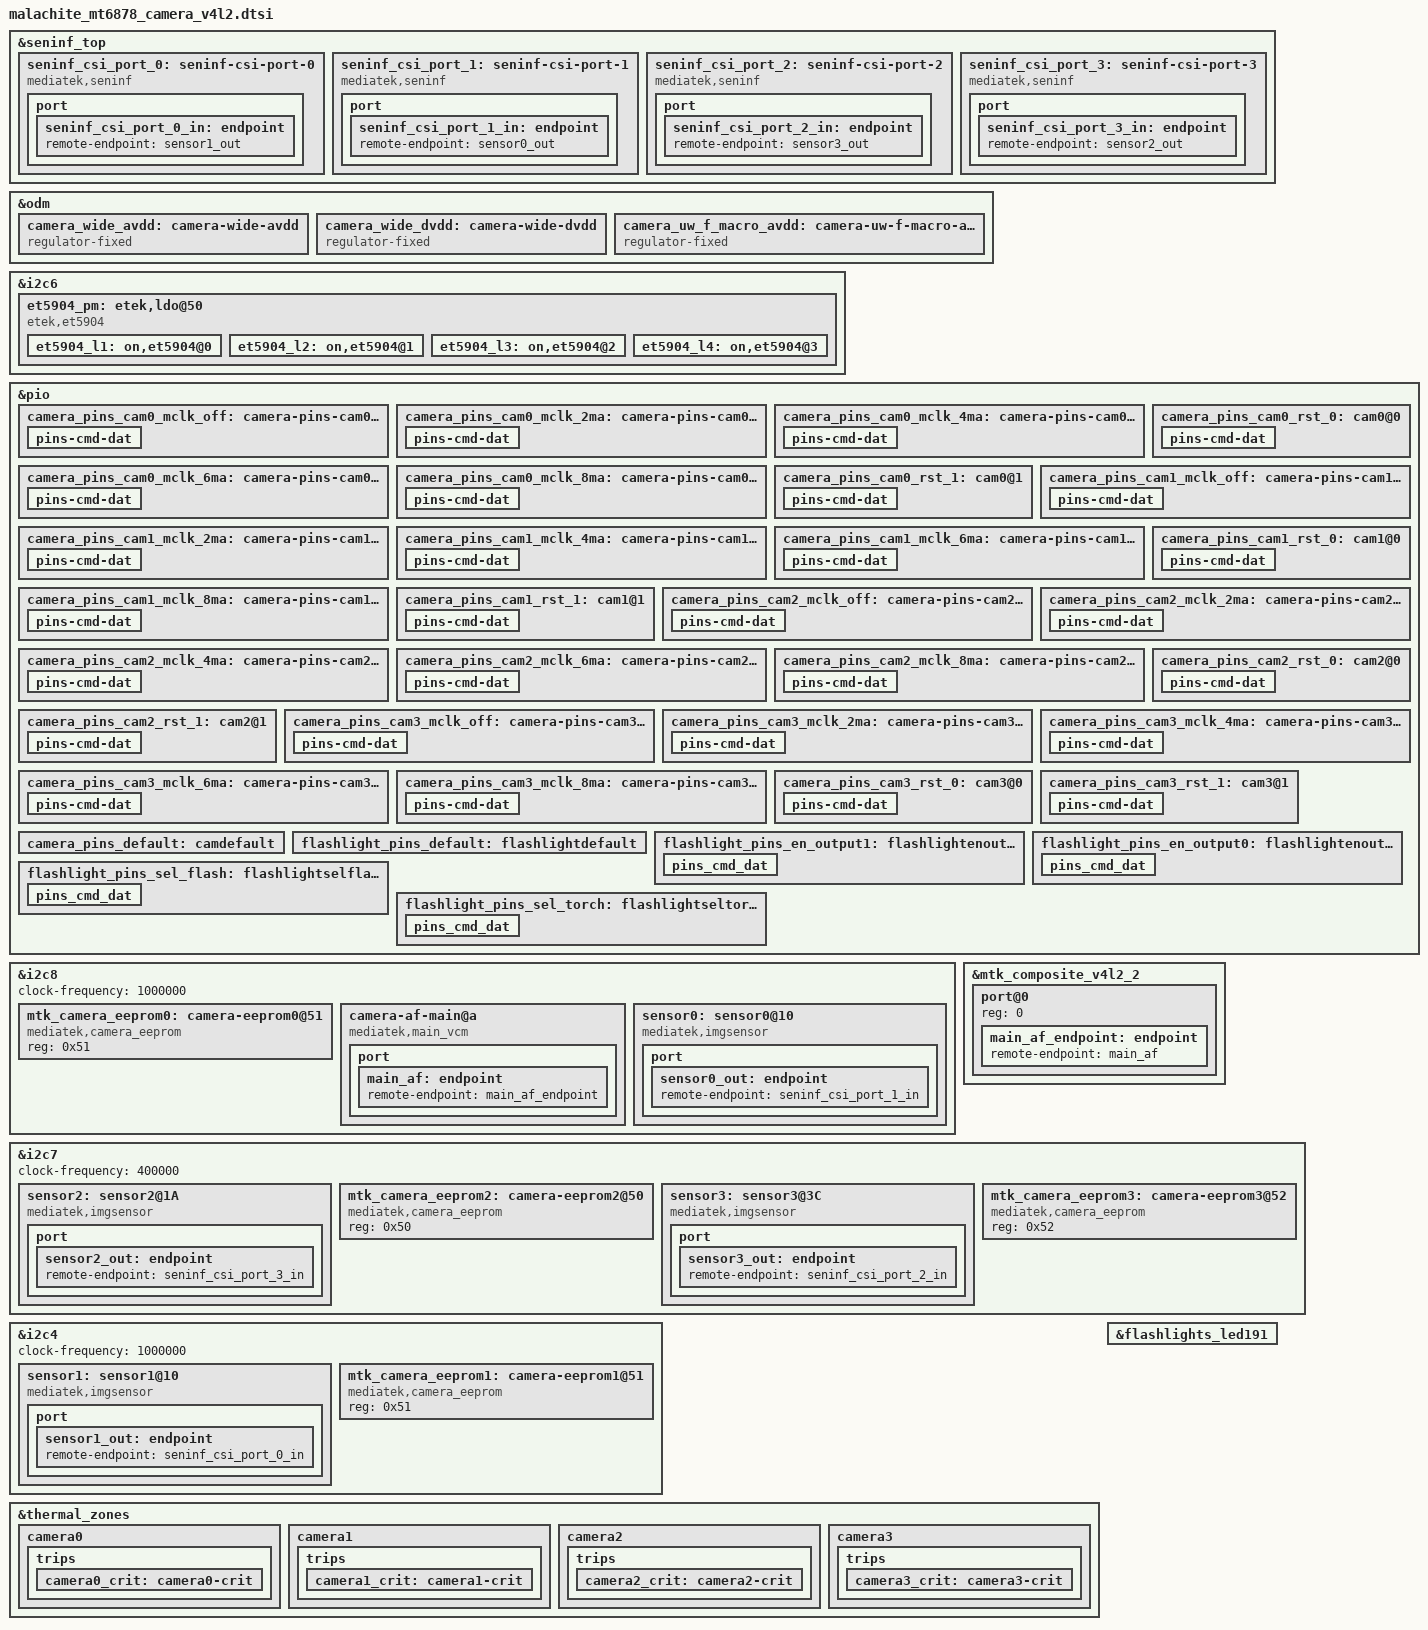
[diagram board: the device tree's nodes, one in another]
// SPDX-License-Identifier: GPL-2.0
/* Copyright (c) 2020 MediaTek Inc. */
#include <dt-bindings/clock/mt6878-clk.h>

&seninf_top {
		seninf_csi_port_0: seninf-csi-port-0 {
			compatible = "mediatek,seninf";
			csi-port = "0";
			nvmem-cells = <&csi_efuse0>;
			nvmem-cell-names = "rg_csi";
			port {
				seninf_csi_port_0_in: endpoint {
					remote-endpoint = <&sensor1_out>;
				};
			};
		};

		seninf_csi_port_1: seninf-csi-port-1 {

			compatible = "mediatek,seninf";
			csi-port = "1";
			nvmem-cells = <&csi_efuse1>;
			nvmem-cell-names = "rg_csi";
			port {
				seninf_csi_port_1_in: endpoint {
					remote-endpoint = <&sensor0_out>;
				};
			};
		};

		seninf_csi_port_2: seninf-csi-port-2 {
			compatible = "mediatek,seninf";
			csi-port = "2B";
			nvmem-cells = <&csi_efuse2>;
			nvmem-cell-names = "rg_csi";
			port {
				seninf_csi_port_2_in: endpoint {
					remote-endpoint = <&sensor3_out>;
				};
			};
		};
		seninf_csi_port_3: seninf-csi-port-3 {
			compatible = "mediatek,seninf";
			csi-port = "3";
			nvmem-cells = <&csi_efuse3>;
			nvmem-cell-names = "rg_csi";
			port {
				seninf_csi_port_3_in: endpoint {
					remote-endpoint = <&sensor2_out>;
				};
			};
		};
};

/* CAMERA GPIO fixed to regulator */
&odm {
	camera_wide_avdd: camera-wide-avdd {
		compatible = "regulator-fixed";
		regulator-name = "camera-wide-avdd";
		regulator-min-microvolt = <2800000>;
		regulator-max-microvolt = <2800000>;
		enable-active-high;
		gpio = <&pio 23 0x0>;
	};
	camera_wide_dvdd: camera-wide-dvdd {
		compatible = "regulator-fixed";
		regulator-name = "camera-wide-dvdd";
		regulator-min-microvolt = <1200000>;
		regulator-max-microvolt = <1200000>;
		enable-active-high;
		gpio = <&pio 191 0x0>;
	};
	camera_uw_f_macro_avdd: camera-uw-f-macro-avdd {
		compatible = "regulator-fixed";
		regulator-name = "camera-uw-f-macro-avdd";
		regulator-min-microvolt = <2800000>;
		regulator-max-microvolt = <2800000>;
		enable-active-high;
		gpio = <&pio 185 0x0>;
	};
};


&i2c6 {
	#address-cells = <1>;
	#size-cells = <0>;

	et5904_pm:etek,ldo@50 {
		compatible = "etek,et5904";
		reg = <0x50>;/*slave address*/
		index = <0>;
		BoardId_gpio1 = <&pio 105 0x0>;
		BoardId_gpio2 = <&pio 106 0x0>;
		BoardId_gpio3 = <&pio 113 0x0>;

		et5904_l1:on,et5904@0{
			offset = /bits/ 16 <0x0000>;
			regulator-name ="et5904-l1";
			regulator-min-microvolt = <528000>;
			regulator-max-microvolt = <1504000>;
			min-dropout-voltage = <225000>;
			init-voltage = <1200000>;
			iout_ua = <650000>;
		};

		et5904_l2:on,et5904@1{
			offset = /bits/ 16 <0x0001>;
			regulator-name ="et5904-l2";
			regulator-min-microvolt = <528000>;
			regulator-max-microvolt = <1504000>;
			min-dropout-voltage = <225000>;
			init-voltage = <1200000>;
			iout_ua = <650000>;
		};

		et5904_l3:on,et5904@2{
			offset = /bits/ 16 <0x0002>;
			regulator-name ="et5904-l3";
			regulator-min-microvolt = <1504000>;
			regulator-max-microvolt = <3400000>;
			min-dropout-voltage = <200000>;
			init-voltage = <2800000>;
			iout_ua = <650000>;
		};

		et5904_l4:on,et5904@3{
			offset = /bits/ 16 <0x0003>;
			regulator-name ="et5904-l4";
			regulator-min-microvolt = <1504000>;
			regulator-max-microvolt = <3400000>;
			min-dropout-voltage = <200000>;
			init-voltage = <2800000>;
			iout_ua = <650000>;
		};

	};
};


/* CAMERA GPIO standardization */
&pio {
	camera_pins_cam0_mclk_off: camera-pins-cam0-mclk-off {
		pins-cmd-dat {
			pinmux = <PINMUX_GPIO93__FUNC_GPIO93>;
			drive-strength = <1>;
		};
	};
	camera_pins_cam0_mclk_2ma: camera-pins-cam0-mclk-2ma {
		pins-cmd-dat {
			pinmux = <PINMUX_GPIO93__FUNC_CMMCLK1>;
			drive-strength = <0>;
		};
	};
	camera_pins_cam0_mclk_4ma: camera-pins-cam0-mclk-4ma {
		pins-cmd-dat {
			pinmux = <PINMUX_GPIO93__FUNC_CMMCLK1>;
			drive-strength = <1>;
		};
	};
	camera_pins_cam0_mclk_6ma: camera-pins-cam0-mclk-6ma {
		pins-cmd-dat {
			pinmux = <PINMUX_GPIO93__FUNC_CMMCLK1>;
			drive-strength = <2>;
		};
	};
	camera_pins_cam0_mclk_8ma: camera-pins-cam0-mclk-8ma {
		pins-cmd-dat {
			pinmux = <PINMUX_GPIO93__FUNC_CMMCLK1>;
			drive-strength = <3>;
		};
	};
	camera_pins_cam0_rst_0: cam0@0 {
		pins-cmd-dat {
			pinmux = <PINMUX_GPIO25__FUNC_GPIO25>;
			slew-rate = <1>;
			output-low;
		};
	};
	camera_pins_cam0_rst_1: cam0@1 {
		pins-cmd-dat {
			pinmux = <PINMUX_GPIO25__FUNC_GPIO25>;
			slew-rate = <1>;
			output-high;
		};
	};

	camera_pins_cam1_mclk_off: camera-pins-cam1-mclk-off {
		pins-cmd-dat {
			pinmux = <PINMUX_GPIO96__FUNC_GPIO96>;
			drive-strength = <1>;
		};
	};
	camera_pins_cam1_mclk_2ma: camera-pins-cam1-mclk-2ma {
		pins-cmd-dat {
			pinmux = <PINMUX_GPIO96__FUNC_CMMCLK4>;
			drive-strength = <0>;
		};
	};
	camera_pins_cam1_mclk_4ma: camera-pins-cam1-mclk-4ma {
		pins-cmd-dat {
			pinmux = <PINMUX_GPIO96__FUNC_CMMCLK4>;
			drive-strength = <1>;
		};
	};
	camera_pins_cam1_mclk_6ma: camera-pins-cam1-mclk-6ma {
		pins-cmd-dat {
			pinmux = <PINMUX_GPIO96__FUNC_CMMCLK4>;
			drive-strength = <2>;
		};
	};
	camera_pins_cam1_mclk_8ma: camera-pins-cam1-mclk-8ma {
		pins-cmd-dat {
			pinmux = <PINMUX_GPIO96__FUNC_CMMCLK4>;
			drive-strength = <3>;
		};
	};
	camera_pins_cam1_rst_0: cam1@0 {
		pins-cmd-dat {
			pinmux = <PINMUX_GPIO24__FUNC_GPIO24>;
			slew-rate = <1>;
			output-low;
		};
	};
	camera_pins_cam1_rst_1: cam1@1 {
		pins-cmd-dat {
			pinmux = <PINMUX_GPIO24__FUNC_GPIO24>;
			slew-rate = <1>;
			output-high;
		};
	};

	camera_pins_cam2_mclk_off: camera-pins-cam2-mclk-off {
		pins-cmd-dat {
			pinmux = <PINMUX_GPIO94__FUNC_GPIO94>;
			drive-strength = <1>;
		};
	};
	camera_pins_cam2_mclk_2ma: camera-pins-cam2-mclk-2ma {
		pins-cmd-dat {
			pinmux = <PINMUX_GPIO94__FUNC_CMMCLK2>;
			drive-strength = <0>;
		};
	};
	camera_pins_cam2_mclk_4ma: camera-pins-cam2-mclk-4ma {
		pins-cmd-dat {
			pinmux = <PINMUX_GPIO94__FUNC_CMMCLK2>;
			drive-strength = <1>;
		};
	};
	camera_pins_cam2_mclk_6ma: camera-pins-cam2-mclk-6ma {
		pins-cmd-dat {
			pinmux = <PINMUX_GPIO94__FUNC_CMMCLK2>;
			drive-strength = <2>;
		};
	};
	camera_pins_cam2_mclk_8ma: camera-pins-cam2-mclk-8ma {
		pins-cmd-dat {
			pinmux = <PINMUX_GPIO94__FUNC_CMMCLK2>;
			drive-strength = <3>;
		};
	};
	camera_pins_cam2_rst_0: cam2@0 {
		pins-cmd-dat {
			pinmux = <PINMUX_GPIO26__FUNC_GPIO26>;
			slew-rate = <1>;
			output-low;
		};
	};
	camera_pins_cam2_rst_1: cam2@1 {
		pins-cmd-dat {
			pinmux = <PINMUX_GPIO26__FUNC_GPIO26>;
			slew-rate = <1>;
			output-high;
		};
	};

	camera_pins_cam3_mclk_off: camera-pins-cam3-mclk-off {
		pins-cmd-dat {
			pinmux = <PINMUX_GPIO95__FUNC_GPIO95>;
			drive-strength = <1>;
		};
	};
	camera_pins_cam3_mclk_2ma: camera-pins-cam3-mclk-2ma {
		pins-cmd-dat {
			pinmux = <PINMUX_GPIO95__FUNC_CMMCLK3>;
			drive-strength = <0>;
		};
	};
	camera_pins_cam3_mclk_4ma: camera-pins-cam3-mclk-4ma {
		pins-cmd-dat {
			pinmux = <PINMUX_GPIO95__FUNC_CMMCLK3>;
			drive-strength = <1>;
		};
	};
	camera_pins_cam3_mclk_6ma: camera-pins-cam3-mclk-6ma {
		pins-cmd-dat {
			pinmux = <PINMUX_GPIO95__FUNC_CMMCLK3>;
			drive-strength = <2>;
		};
	};
	camera_pins_cam3_mclk_8ma: camera-pins-cam3-mclk-8ma {
		pins-cmd-dat {
			pinmux = <PINMUX_GPIO95__FUNC_CMMCLK3>;
			drive-strength = <3>;
		};
	};
	camera_pins_cam3_rst_0: cam3@0 {
		pins-cmd-dat {
			pinmux = <PINMUX_GPIO27__FUNC_GPIO27>;
			slew-rate = <1>;
			output-low;
		};
	};
	camera_pins_cam3_rst_1: cam3@1 {
		pins-cmd-dat {
			pinmux = <PINMUX_GPIO27__FUNC_GPIO27>;
			slew-rate = <1>;
			output-high;
		};
	};
	camera_pins_default: camdefault {
	};
};
/* CAMERA GPIO end */
&i2c8 {
	status = "okay";
	clock-frequency = <1000000>;

	mtk_camera_eeprom0:camera-eeprom0@51 {
		compatible = "mediatek,camera_eeprom";
		reg = <0x51>;
		status = "okay";
	};
	camera-af-main@a {
		compatible = "mediatek,main_vcm";
		reg = <0x0a>;
		vin-supply = <&et5904_l4>;
		port {
			main_af: endpoint {
				remote-endpoint = <&main_af_endpoint>;
			};
		};
	};
	sensor0: sensor0@10 {
		compatible = "mediatek,imgsensor";
		sensor-names = "malachiteimx882wide_mipi_raw","malachites5khp3wide_mipi_raw";
		reg = <0x10>;
		BoardId_gpio1 = <&pio 105 0x0>;
		BoardId_gpio2 = <&pio 106 0x0>;
		BoardId_gpio3 = <&pio 113 0x0>;
		#thermal-sensor-cells = <0>;

		pinctrl-names = "mclk_off",
				"mclk_2mA",
				"mclk_4mA",
				"mclk_6mA",
				"mclk_8mA",
				"rst_low",
				"rst_high";
		pinctrl-0 = <&camera_pins_cam0_mclk_off>;
		pinctrl-1 = <&camera_pins_cam0_mclk_2ma>;
		pinctrl-2 = <&camera_pins_cam0_mclk_4ma>;
		pinctrl-3 = <&camera_pins_cam0_mclk_6ma>;
		pinctrl-4 = <&camera_pins_cam0_mclk_8ma>;
		pinctrl-5 = <&camera_pins_cam0_rst_0>;
		pinctrl-6 = <&camera_pins_cam0_rst_1>;

		avdd-supply = <&camera_wide_avdd>;
		dvdd-supply = <&camera_wide_dvdd>;
		dvdd1-supply = <&et5904_l1>;
		dovdd-supply = <&mt6363_vio18>;
		avdd1-supply = <&et5904_l3>;

		clocks = <&topckgen_clk CLK_TOP_UVPLL192M_D32>,
			<&topckgen_clk CLK_TOP_UVPLL192M_D16>,
			<&topckgen_clk CLK_TOP_OSC_D20>,
			<&topckgen_clk CLK_TOP_UVPLL192M_D10>,
			<&topckgen_clk CLK_TOP_UVPLL192M_D8>,
			<&topckgen_clk CLK_TOP_TCK_26M_MX9>,
			<&topckgen_clk CLK_TOP_UNIVPLL_D6_D8>,
			<&topckgen_clk CLK_TOP_CAMTG2_SEL>;
		clock-names = "6", "12", "13", "19.2", "24", "26", "52", "mclk";

		status = "okay";
		port {
			sensor0_out: endpoint {
				remote-endpoint = <&seninf_csi_port_1_in>;
			};
		};
	};
};
&mtk_composite_v4l2_2 {
	#address-cells = <1>;
	#size-cells = <0>;
	port@0 {
		reg = <0>;
		main_af_endpoint: endpoint {
			remote-endpoint = <&main_af>;
		};
	};
};
&i2c7 {
	status = "okay";
	clock-frequency = <400000>;

	sensor2: sensor2@1A {
		compatible = "mediatek,imgsensor";
		sensor-names = "malachiteimx355ultra_mipi_raw";
		reg = <0x10>;

		#thermal-sensor-cells = <0>;

		pinctrl-names = "mclk_off",
				"mclk_2mA",
				"mclk_4mA",
				"mclk_6mA",
				"mclk_8mA",
				"rst_low",
				"rst_high";
		pinctrl-0 = <&camera_pins_cam2_mclk_off>;
		pinctrl-1 = <&camera_pins_cam2_mclk_2ma>;
		pinctrl-2 = <&camera_pins_cam2_mclk_4ma>;
		pinctrl-3 = <&camera_pins_cam2_mclk_6ma>;
		pinctrl-4 = <&camera_pins_cam2_mclk_8ma>;
		pinctrl-5 = <&camera_pins_cam2_rst_0>;
		pinctrl-6 = <&camera_pins_cam2_rst_1>;

		avdd-supply = <&camera_uw_f_macro_avdd>;
		dvdd-supply = <&et5904_l2>;
		dovdd-supply = <&mt6363_vio18>;

		clocks = <&topckgen_clk CLK_TOP_UVPLL192M_D32>,
			<&topckgen_clk CLK_TOP_UVPLL192M_D16>,
			<&topckgen_clk CLK_TOP_OSC_D20>,
			<&topckgen_clk CLK_TOP_UVPLL192M_D10>,
			<&topckgen_clk CLK_TOP_UVPLL192M_D8>,
			<&topckgen_clk CLK_TOP_TCK_26M_MX9>,
			<&topckgen_clk CLK_TOP_UNIVPLL_D6_D8>,
			<&topckgen_clk CLK_TOP_CAMTG3_SEL>;
		clock-names = "6", "12", "13", "19.2", "24", "26", "52", "mclk";

		status = "okay";
		port {
			sensor2_out: endpoint {
				remote-endpoint = <&seninf_csi_port_3_in>;
			};
		};
	};

	mtk_camera_eeprom2:camera-eeprom2@50 {
		compatible = "mediatek,camera_eeprom";
		reg = <0x50>;
		status = "okay";
	};

	sensor3: sensor3@3C {
		compatible = "mediatek,imgsensor";
		sensor-names = "malachiteov02b10macro_mipi_raw";
		reg = <0x3C>;

		#thermal-sensor-cells = <0>;

		pinctrl-names = "mclk_off",
				"mclk_2mA",
				"mclk_4mA",
				"mclk_6mA",
				"mclk_8mA",
				"rst_low",
				"rst_high";
		pinctrl-0 = <&camera_pins_cam3_mclk_off>;
		pinctrl-1 = <&camera_pins_cam3_mclk_2ma>;
		pinctrl-2 = <&camera_pins_cam3_mclk_4ma>;
		pinctrl-3 = <&camera_pins_cam3_mclk_6ma>;
		pinctrl-4 = <&camera_pins_cam3_mclk_8ma>;
		pinctrl-5 = <&camera_pins_cam3_rst_0>;
		pinctrl-6 = <&camera_pins_cam3_rst_1>;

		avdd-supply = <&camera_uw_f_macro_avdd>;
		dovdd-supply = <&mt6363_vio18>;

		clocks = <&topckgen_clk CLK_TOP_UVPLL192M_D32>,
			<&topckgen_clk CLK_TOP_UVPLL192M_D16>,
			<&topckgen_clk CLK_TOP_OSC_D20>,
			<&topckgen_clk CLK_TOP_UVPLL192M_D10>,
			<&topckgen_clk CLK_TOP_UVPLL192M_D8>,
			<&topckgen_clk CLK_TOP_TCK_26M_MX9>,
			<&topckgen_clk CLK_TOP_UNIVPLL_D6_D8>,
			<&topckgen_clk CLK_TOP_CAMTG4_SEL>;
		clock-names = "6", "12", "13", "19.2", "24", "26", "52", "mclk";

		status = "okay";
		port {
			sensor3_out: endpoint {
				remote-endpoint = <&seninf_csi_port_2_in>;
			};
		};
	};

	mtk_camera_eeprom3:camera-eeprom3@52 {
		compatible = "mediatek,camera_eeprom";
		reg = <0x52>;
		status = "okay";
	};
};

&i2c4 {
	status = "okay";
	clock-frequency = <1000000>;

	sensor1: sensor1@10 {
		compatible = "mediatek,imgsensor";
		sensor-names = "malachiteov20bfront_mipi_raw";
		reg = <0x10>;

		pinctrl-names = "mclk_off",
				"mclk_2mA",
				"mclk_4mA",
				"mclk_6mA",
				"mclk_8mA",
				"rst_low",
				"rst_high";
		pinctrl-0 = <&camera_pins_cam1_mclk_off>;
		pinctrl-1 = <&camera_pins_cam1_mclk_2ma>;
		pinctrl-2 = <&camera_pins_cam1_mclk_4ma>;
		pinctrl-3 = <&camera_pins_cam1_mclk_6ma>;
		pinctrl-4 = <&camera_pins_cam1_mclk_8ma>;
		pinctrl-5 = <&camera_pins_cam1_rst_0>;
		pinctrl-6 = <&camera_pins_cam1_rst_1>;

		avdd-supply = <&camera_uw_f_macro_avdd>;
		dvdd-supply = <&et5904_l2>;
		dovdd-supply = <&mt6363_vio18>;

		clocks = <&topckgen_clk CLK_TOP_UVPLL192M_D32>,
			<&topckgen_clk CLK_TOP_UVPLL192M_D16>,
			<&topckgen_clk CLK_TOP_OSC_D20>,
			<&topckgen_clk CLK_TOP_UVPLL192M_D10>,
			<&topckgen_clk CLK_TOP_UVPLL192M_D8>,
			<&topckgen_clk CLK_TOP_TCK_26M_MX9>,
			<&topckgen_clk CLK_TOP_UNIVPLL_D6_D8>,
			<&topckgen_clk CLK_TOP_CAMTG5_SEL>;
		clock-names = "6", "12", "13", "19.2", "24", "26", "52", "mclk";

		status = "okay";
		port {
			sensor1_out: endpoint {
				remote-endpoint = <&seninf_csi_port_0_in>;
			};
		};
	};

	mtk_camera_eeprom1:camera-eeprom1@51 {
		compatible = "mediatek,camera_eeprom";
		reg = <0x51>;
		status = "okay";
	};
};

&thermal_zones {
	camera0: camera0 {
		polling-delay = <0>; /* milliseconds */
		polling-delay-passive = <0>; /* milliseconds */
		thermal-sensors = <&sensor0>;
		trips {
			camera0_crit: camera0-crit {
				temperature = <120000>;
				hysteresis = <2000>;
				type = "passive";
			};
		};
	};
	camera1: camera1 {
		polling-delay = <0>; /* milliseconds */
		polling-delay-passive = <0>; /* milliseconds */
		thermal-sensors = <&sensor1>;
		trips {
			camera1_crit: camera1-crit {
				temperature = <120000>;
				hysteresis = <2000>;
				type = "passive";
			};
		};
	};
	camera2: camera2 {
		polling-delay = <0>; /* milliseconds */
		polling-delay-passive = <0>; /* milliseconds */
		thermal-sensors = <&sensor2>;
		trips {
			camera2_crit: camera2-crit {
				temperature = <120000>;
				hysteresis = <2000>;
				type = "passive";
			};
		};
	};
	camera3: camera3 {
		polling-delay = <0>; /* milliseconds */
		polling-delay-passive = <0>; /* milliseconds */
		thermal-sensors = <&sensor3>;
		trips {
			camera3_crit: camera3-crit {
				temperature = <120000>;
				hysteresis = <2000>;
				type = "passive";
			};
		};
	};
};

&flashlights_led191 {
        pinctrl-names = "default", "hwen_high",
                "hwen_low", "hwsel_high",
                "hwsel_low";
        pinctrl-0 = <&flashlight_pins_default>;
        pinctrl-1 = <&flashlight_pins_en_output1>;
        pinctrl-2 = <&flashlight_pins_en_output0>;
        pinctrl-3 = <&flashlight_pins_sel_flash>;
        pinctrl-4 = <&flashlight_pins_sel_torch>;
        status = "okay";
};
&pio {
        flashlight_pins_default: flashlightdefault {
        };
        flashlight_pins_en_output1: flashlightenoutput1 {
                pins_cmd_dat {
                        pinmux = <PINMUX_GPIO195__FUNC_GPIO195>;
                        slew-rate = <1>;
                        output-high;
                };
        };
        flashlight_pins_en_output0: flashlightenoutput0 {
                pins_cmd_dat {
                        pinmux = <PINMUX_GPIO195__FUNC_GPIO195>;
                        slew-rate = <1>;
                        output-low;
                };
        };
        flashlight_pins_sel_flash: flashlightselflash {
                pins_cmd_dat {
                        pinmux = <PINMUX_GPIO153__FUNC_GPIO153>;
                        slew-rate = <1>;
                        output-low;
                };
        };
        flashlight_pins_sel_torch: flashlightseltorch {
                pins_cmd_dat {
                        pinmux = <PINMUX_GPIO153__FUNC_GPIO153>;
                        slew-rate = <0>;
                        bias-disable;
                };
        };
};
